VERSION ""

NS_ :

BS_:

BU_:

BO_ 567 Virtual_CAN_ADC: 2 Vector__XXX
 SG_ ADC1 : 7|16@0+ (0.0009765625,0) [0|0] "V" Vector__XXX

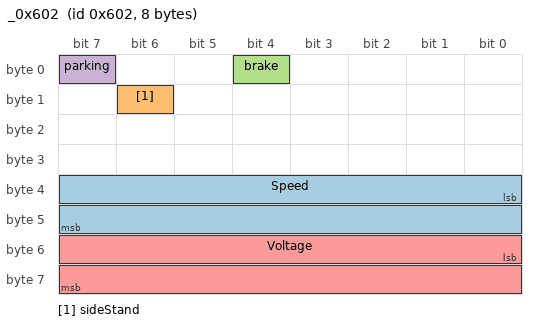
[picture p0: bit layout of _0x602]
BO_ 1538 _0x602: 8 Vector__XXX
 SG_ Speed : 32|16@1+ (0.1,0) [0|6553.5] "Km/h" Vector__XXX
 SG_ sideStand : 14|1@1- (1,0) [0|1] "" Vector__XXX
 SG_ brake : 4|1@1- (1,0) [0|1] "" Vector__XXX
 SG_ parking : 7|1@1- (1,0) [0|1] "" Vector__XXX
 SG_ Voltage : 48|16@1+ (0.1,0) [0|6553.5] "V" Vector__XXX

BO_ 1539 _0x603: 4 Vector__XXX
 SG_ Mileage : 0|16@1+ (0.1,0) [0|6553.5] "" Vector__XXX

BA_DEF_  "BusType" STRING ;
BA_DEF_DEF_  "BusType" "";
BA_ "BusType" "CAN";
